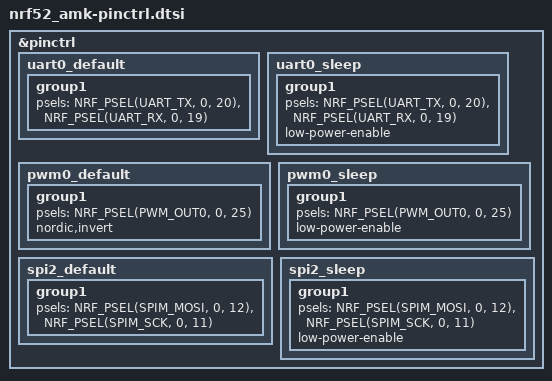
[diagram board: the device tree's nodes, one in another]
/*
 * Copyright (c) 2022 Nordic Semiconductor ASA
 *
 * SPDX-License-Identifier: LicenseRef-Nordic-5-Clause
 */

&pinctrl {
	uart0_default: uart0_default {
		group1 {
			psels = <NRF_PSEL(UART_TX, 0, 20)>,
				<NRF_PSEL(UART_RX, 0, 19)>;
		};
	};

	uart0_sleep: uart0_sleep {
		group1 {
			psels = <NRF_PSEL(UART_TX, 0, 20)>,
				<NRF_PSEL(UART_RX, 0, 19)>;
			low-power-enable;
		};
	};

	pwm0_default: pwm0_default {
		group1 {
			psels = <NRF_PSEL(PWM_OUT0, 0, 25)>;
			nordic,invert;
		};
	};

	pwm0_sleep: pwm0_sleep {
		group1 {
			psels = <NRF_PSEL(PWM_OUT0, 0, 25)>;
			low-power-enable;
		};
	};

	spi2_default: spi2_default {
		group1 {
			psels = <NRF_PSEL(SPIM_MOSI, 0, 12)>,
					<NRF_PSEL(SPIM_SCK, 0, 11)>;
		};
	};

	spi2_sleep: spi2_sleep {
		group1 {
			psels = <NRF_PSEL(SPIM_MOSI, 0, 12)>,
					<NRF_PSEL(SPIM_SCK, 0, 11)>;
			low-power-enable;
		};
	};

};
